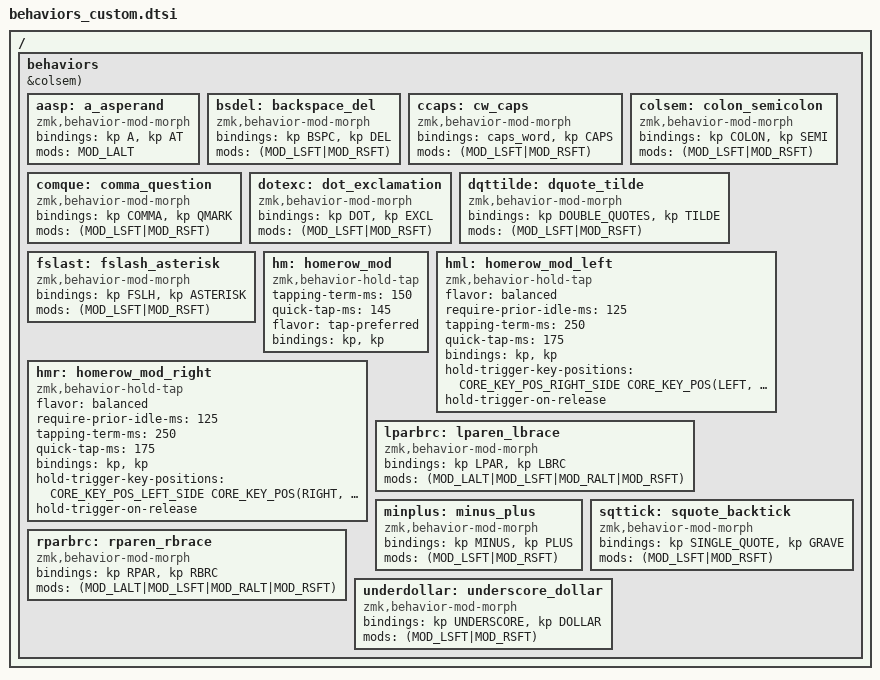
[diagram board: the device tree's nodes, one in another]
#include "positions.h"
#include "utils.h"
#include <behaviors.dtsi>

/ {
    behaviors {
        LINGER_KEY(ln_col, &kp COLON &kp U &kp P &kp RET, &colsem);

        aasp: a_asperand {
            compatible = "zmk,behavior-mod-morph";
            #binding-cells = <0>;
            bindings = <&kp A>, <&kp AT>;
            mods = <MOD_LALT>;
        };

        bsdel: backspace_del {
            compatible = "zmk,behavior-mod-morph";
            #binding-cells = <0>;
            bindings = <&kp BSPC>, <&kp DEL>;
            mods = <(MOD_LSFT|MOD_RSFT)>;
        };

        ccaps: cw_caps {
            compatible = "zmk,behavior-mod-morph";
            #binding-cells = <0>;
            bindings = <&caps_word>, <&kp CAPS>;
            mods = <(MOD_LSFT|MOD_RSFT)>;
        };

        colsem: colon_semicolon {
            compatible = "zmk,behavior-mod-morph";
            #binding-cells = <0>;
            bindings = <&kp COLON>, <&kp SEMI>;
            mods = <(MOD_LSFT|MOD_RSFT)>;
        };

        comque: comma_question {
            compatible = "zmk,behavior-mod-morph";
            #binding-cells = <0>;
            bindings = <&kp COMMA>, <&kp QMARK>;
            mods = <(MOD_LSFT|MOD_RSFT)>;
        };

        dotexc: dot_exclamation {
            compatible = "zmk,behavior-mod-morph";
            #binding-cells = <0>;
            bindings = <&kp DOT>, <&kp EXCL>;
            mods = <(MOD_LSFT|MOD_RSFT)>;
        };

        dqttilde: dquote_tilde {
            compatible = "zmk,behavior-mod-morph";
            #binding-cells = <0>;
            bindings = <&kp DOUBLE_QUOTES>, <&kp TILDE>;
            mods = <(MOD_LSFT|MOD_RSFT)>;
        };

        fslast: fslash_asterisk {
            compatible = "zmk,behavior-mod-morph";
            #binding-cells = <0>;
            bindings = <&kp FSLH>, <&kp ASTERISK>;
            mods = <(MOD_LSFT|MOD_RSFT)>;
        };

        hm: homerow_mod {
            compatible = "zmk,behavior-hold-tap";
            #binding-cells = <2>;
            tapping-term-ms = <150>;
            quick-tap-ms = <145>;
            flavor = "tap-preferred";
            bindings = <&kp>, <&kp>;
        };

        hml: homerow_mod_left {
            compatible = "zmk,behavior-hold-tap";
            #binding-cells = <2>;
            flavor = "balanced";
            require-prior-idle-ms = <125>;
            tapping-term-ms = <250>;
            quick-tap-ms = <175>;
            bindings = <&kp>, <&kp>;
            hold-trigger-key-positions = <CORE_KEY_POS_RIGHT_SIDE CORE_KEY_POS(LEFT, 3, 2) CORE_KEY_POS(LEFT, 3, 3) CORE_KEY_POS(LEFT, 3, 4)>;
            hold-trigger-on-release;
        };

        hmr: homerow_mod_right {
            compatible = "zmk,behavior-hold-tap";
            #binding-cells = <2>;
            flavor = "balanced";
            require-prior-idle-ms = <125>;
            tapping-term-ms = <250>;
            quick-tap-ms = <175>;
            bindings = <&kp>, <&kp>;
            hold-trigger-key-positions = <CORE_KEY_POS_LEFT_SIDE CORE_KEY_POS(RIGHT, 3, 0) CORE_KEY_POS(RIGHT, 3, 1) CORE_KEY_POS(RIGHT, 3, 2)>;
            hold-trigger-on-release;
        };

        lparbrc: lparen_lbrace {
            compatible = "zmk,behavior-mod-morph";
            #binding-cells = <0>;
            bindings = <&kp LPAR>, <&kp LBRC>;
            mods = <(MOD_LALT|MOD_LSFT|MOD_RALT|MOD_RSFT)>;
        };

        minplus: minus_plus {
            compatible = "zmk,behavior-mod-morph";
            #binding-cells = <0>;
            bindings = <&kp MINUS>, <&kp PLUS>;
            mods = <(MOD_LSFT|MOD_RSFT)>;
        };

        rparbrc: rparen_rbrace {
            compatible = "zmk,behavior-mod-morph";
            #binding-cells = <0>;
            bindings = <&kp RPAR>, <&kp RBRC>;
            mods = <(MOD_LALT|MOD_LSFT|MOD_RALT|MOD_RSFT)>;
        };

        sqttick: squote_backtick {
            compatible = "zmk,behavior-mod-morph";
            #binding-cells = <0>;
            bindings = <&kp SINGLE_QUOTE>, <&kp GRAVE>;
            mods = <(MOD_LSFT|MOD_RSFT)>;
        };

        underdollar: underscore_dollar {
            compatible = "zmk,behavior-mod-morph";
            #binding-cells = <0>;
            bindings = <&kp UNDERSCORE>, <&kp DOLLAR>;
            mods = <(MOD_LSFT|MOD_RSFT)>;
        };
    };
};
